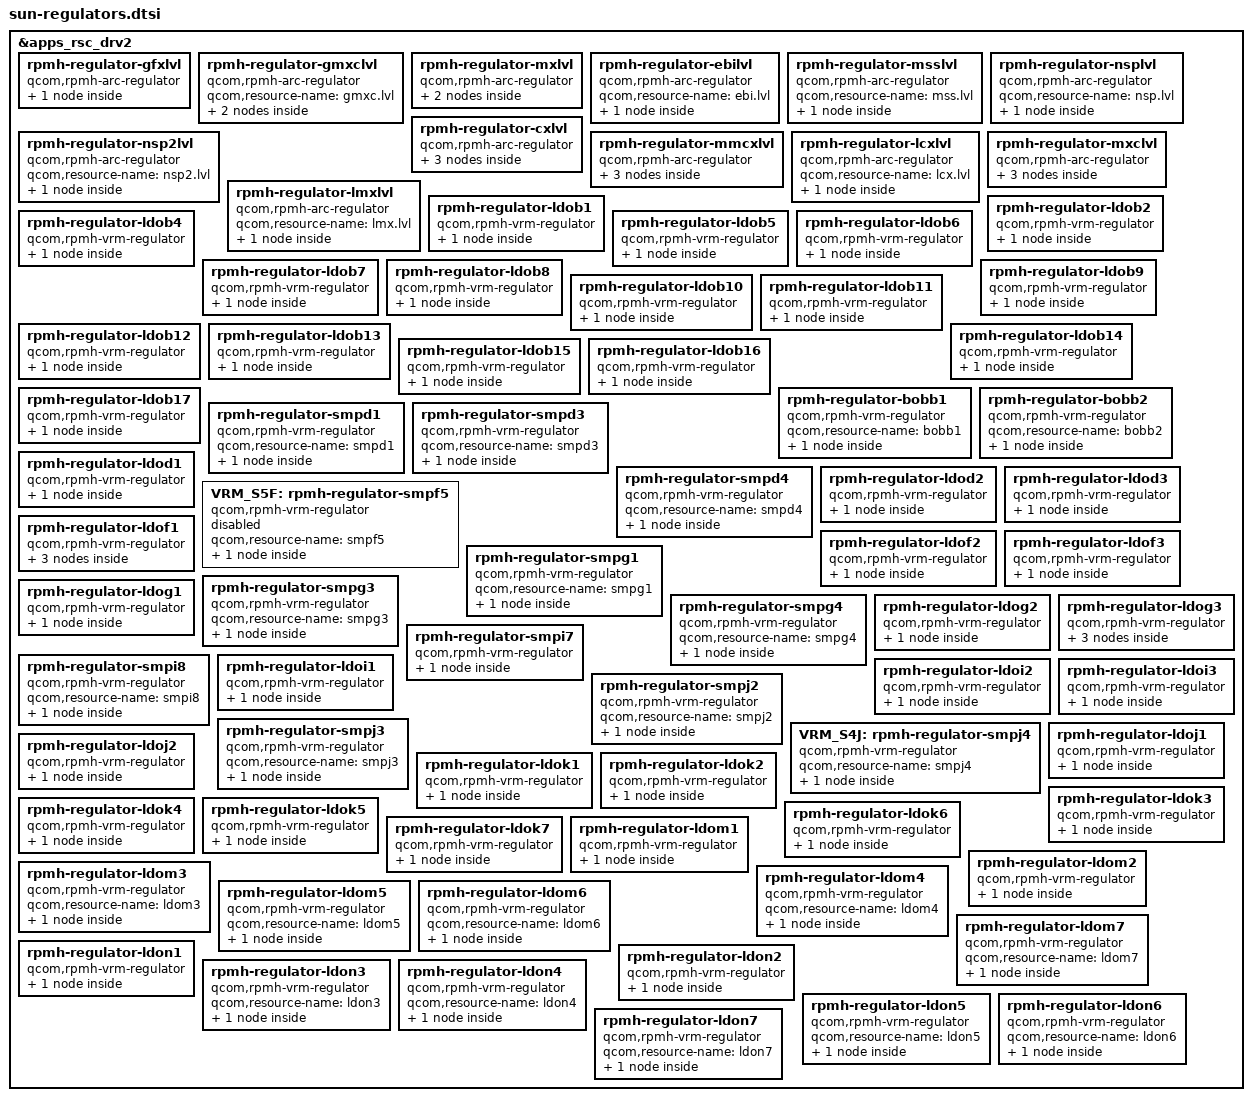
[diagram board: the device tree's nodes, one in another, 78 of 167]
// SPDX-License-Identifier: BSD-3-Clause
/*
 * Copyright (c) 2023-2024 Qualcomm Innovation Center, Inc. All rights reserved.
 */

#include <dt-bindings/regulator/qcom,rpmh-regulator-levels.h>

&apps_rsc_drv2 {
	rpmh-regulator-gfxlvl {
		compatible = "qcom,rpmh-arc-regulator";
		qcom,resource-name = "gfx.lvl";
		proxy-supply = <&VDD_GFX_LEVEL>;

		VDD_GFX_LEVEL: S5D_LEVEL:
		pm_v8d_s5_level: regulator-pm-v8d-s5-level {
			regulator-name = "pm_v8d_s5_level";
			qcom,set = <RPMH_REGULATOR_SET_ALL>;
			regulator-min-microvolt =
				<RPMH_REGULATOR_LEVEL_RETENTION>;
			regulator-max-microvolt =
				<RPMH_REGULATOR_LEVEL_MAX>;
			qcom,init-voltage-level =
				<RPMH_REGULATOR_LEVEL_RETENTION>;
			qcom,proxy-consumer-enable;
			qcom,proxy-consumer-voltage =
				<RPMH_REGULATOR_LEVEL_LOW_SVS
				 RPMH_REGULATOR_LEVEL_MAX>;
		};
	};

	rpmh-regulator-gmxclvl {
		compatible = "qcom,rpmh-arc-regulator";
		qcom,resource-name = "gmxc.lvl";

		VDD_GFX_MXC_LEVEL: S2D_LEVEL:
		pm_v8d_s2_level: regulator-pm-v8d-s2-level {
			regulator-name = "pm_v8d_s2_level";
			qcom,set = <RPMH_REGULATOR_SET_ALL>;
			regulator-min-microvolt =
				<RPMH_REGULATOR_LEVEL_RETENTION>;
			regulator-max-microvolt =
				<RPMH_REGULATOR_LEVEL_MAX>;
			qcom,init-voltage-level =
				<RPMH_REGULATOR_LEVEL_RETENTION>;
		};

		VDD_GFX_MXC_GFX_VOTER_LEVEL: VDD_GFX_GFX_MXC_VOTER_LEVEL:
		regulator-pm-v8d-s2-gfx-voter-level {
			regulator-name = "pm_v8d_s2_gfx_voter_level";
			pm_v8d_s2_gfx_voter_level-parent-supply =
				<&VDD_GFX_LEVEL>;
			qcom,set = <RPMH_REGULATOR_SET_ALL>;
			regulator-min-microvolt =
				<RPMH_REGULATOR_LEVEL_MIN_SVS>;
			regulator-max-microvolt =
				<RPMH_REGULATOR_LEVEL_MAX>;
			qcom,init-voltage-level =
				<RPMH_REGULATOR_LEVEL_MIN_SVS>;
		};
	};

	rpmh-regulator-mxlvl {
		compatible = "qcom,rpmh-arc-regulator";
		qcom,resource-name = "mx.lvl";
		proxy-supply = <&VDD_MXA_LEVEL>;

		VDD_MXA_LEVEL: VDD_MX_LEVEL: S6F_LEVEL:
		pm_v6f_s6_level: S8F_LEVEL: pm_v8f_s8_level:
		regulator-vdd-mxa-level {
			regulator-name = "pm_v6f_s6_level";
			qcom,set = <RPMH_REGULATOR_SET_ALL>;
			regulator-min-microvolt =
				<RPMH_REGULATOR_LEVEL_RETENTION>;
			regulator-max-microvolt =
				<RPMH_REGULATOR_LEVEL_MAX>;
			qcom,init-voltage-level =
				<RPMH_REGULATOR_LEVEL_TURBO>;
			qcom,proxy-consumer-enable;
			qcom,proxy-consumer-voltage =
				<RPMH_REGULATOR_LEVEL_TURBO
				 RPMH_REGULATOR_LEVEL_MAX>;
		};

		VDD_MXA_LEVEL_AO: VDD_MX_LEVEL_AO: S6F_LEVEL_AO:
		pm_v6f_s6_level_ao: S8F_LEVEL_AO: pm_v8f_s8_level_ao:
		regulator-vdd-mxa-level-ao {
			regulator-name = "pm_v6f_s6_level_ao";
			qcom,set = <RPMH_REGULATOR_SET_ACTIVE>;
			regulator-min-microvolt =
				<RPMH_REGULATOR_LEVEL_RETENTION>;
			regulator-max-microvolt =
				<RPMH_REGULATOR_LEVEL_MAX>;
			qcom,init-voltage-level =
				<RPMH_REGULATOR_LEVEL_RETENTION>;
		};
	};

	rpmh-regulator-ebilvl {
		compatible = "qcom,rpmh-arc-regulator";
		qcom,resource-name = "ebi.lvl";

		VDD_EBI_LEVEL: S2G_LEVEL:
		pm_v8g_s2_level: regulator-pm-v8g-s2-level {
			regulator-name = "pm_v8g_s2_level";
			qcom,set = <RPMH_REGULATOR_SET_ALL>;
			regulator-min-microvolt =
				<RPMH_REGULATOR_LEVEL_RETENTION>;
			regulator-max-microvolt =
				<RPMH_REGULATOR_LEVEL_MAX>;
			qcom,init-voltage-level =
				<RPMH_REGULATOR_LEVEL_RETENTION>;
		};
	};

	rpmh-regulator-msslvl {
		compatible = "qcom,rpmh-arc-regulator";
		qcom,resource-name = "mss.lvl";

		VDD_MODEM_LEVEL: S5G_LEVEL:
		pm_v8g_s5_level: regulator-pm-v8g-s5-level {
			regulator-name = "pm_v8g_s5_level";
			qcom,set = <RPMH_REGULATOR_SET_ALL>;
			regulator-min-microvolt =
				<RPMH_REGULATOR_LEVEL_RETENTION>;
			regulator-max-microvolt =
				<RPMH_REGULATOR_LEVEL_MAX>;
			qcom,init-voltage-level =
				<RPMH_REGULATOR_LEVEL_RETENTION>;
		};
	};

	rpmh-regulator-nsplvl {
		compatible = "qcom,rpmh-arc-regulator";
		qcom,resource-name = "nsp.lvl";

		VDD_NSP1_LEVEL: S7G_LEVEL:
		pm_v8g_s7_level: regulator-pm-v8g-s7-level {
			regulator-name = "pm_v8g_s7_level";
			qcom,set = <RPMH_REGULATOR_SET_ALL>;
			regulator-min-microvolt =
				<RPMH_REGULATOR_LEVEL_RETENTION>;
			regulator-max-microvolt =
				<RPMH_REGULATOR_LEVEL_MAX>;
			qcom,init-voltage-level =
				<RPMH_REGULATOR_LEVEL_RETENTION>;
		};
	};

	rpmh-regulator-nsp2lvl {
		compatible = "qcom,rpmh-arc-regulator";
		qcom,resource-name = "nsp2.lvl";

		VDD_NSP2_LEVEL: S1I_LEVEL:
		pm_v8i_s1_level: regulator-pm-v8i-s1-level {
			regulator-name = "pm_v8i_s1_level";
			qcom,set = <RPMH_REGULATOR_SET_ALL>;
			regulator-min-microvolt =
				<RPMH_REGULATOR_LEVEL_RETENTION>;
			regulator-max-microvolt =
				<RPMH_REGULATOR_LEVEL_MAX>;
			qcom,init-voltage-level =
				<RPMH_REGULATOR_LEVEL_RETENTION>;
		};
	};

	rpmh-regulator-cxlvl {
		compatible = "qcom,rpmh-arc-regulator";
		qcom,resource-name = "cx.lvl";
		proxy-supply = <&VDD_CX_LEVEL>;

		VDD_CX_LEVEL: S1J_LEVEL:
		pm_v6j_s1_level: regulator-pm-v6j-s1-level {
			regulator-name = "pm_v6j_s1_level";
			qcom,set = <RPMH_REGULATOR_SET_ALL>;
			regulator-min-microvolt =
				<RPMH_REGULATOR_LEVEL_RETENTION>;
			regulator-max-microvolt =
				<RPMH_REGULATOR_LEVEL_MAX>;
			qcom,init-voltage-level =
				<RPMH_REGULATOR_LEVEL_TURBO>;
			qcom,proxy-consumer-enable;
			qcom,proxy-consumer-voltage =
				<RPMH_REGULATOR_LEVEL_TURBO
				 RPMH_REGULATOR_LEVEL_MAX>;
		};

		VDD_CX_LEVEL_AO: S1J_LEVEL_AO:
		pm_v6j_s1_level_ao: regulator-pm-v6j-s1-level-ao {
			regulator-name = "pm_v6j_s1_level_ao";
			qcom,set = <RPMH_REGULATOR_SET_ACTIVE>;
			regulator-min-microvolt =
				<RPMH_REGULATOR_LEVEL_RETENTION>;
			regulator-max-microvolt =
				<RPMH_REGULATOR_LEVEL_MAX>;
			qcom,init-voltage-level =
				<RPMH_REGULATOR_LEVEL_RETENTION>;
		};

		VDD_CX_MMCX_SUPPLY_LEVEL: regulator-pm-v6j-s1-mmcx-sup-level {
			regulator-name = "pm_v6j_s1_mmcx_sup_level";
			qcom,set = <RPMH_REGULATOR_SET_ALL>;
			regulator-min-microvolt =
				<RPMH_REGULATOR_LEVEL_MIN_SVS>;
			regulator-max-microvolt =
				<RPMH_REGULATOR_LEVEL_MAX>;
			qcom,init-voltage-level =
				<RPMH_REGULATOR_LEVEL_MIN_SVS>;
		};
	};

	rpmh-regulator-mmcxlvl {
		compatible = "qcom,rpmh-arc-regulator";
		qcom,resource-name = "mmcx.lvl";
		proxy-supply = <&VDD_MMCX_LEVEL>;

		VDD_MMCX_LEVEL: VDD_MM_LEVEL: S3I_LEVEL:
		pm_v8i_s3_level: regulator-pm-v8i-s3-level {
			regulator-name = "pm_v8i_s3_level";
			qcom,set = <RPMH_REGULATOR_SET_ALL>;
			pm_v8i_s3_level-parent-supply =
				<&VDD_CX_MMCX_SUPPLY_LEVEL>;
			regulator-min-microvolt =
				<RPMH_REGULATOR_LEVEL_LOW_SVS_D1>;
			regulator-max-microvolt =
				<RPMH_REGULATOR_LEVEL_MAX>;
			qcom,init-voltage-level =
				<RPMH_REGULATOR_LEVEL_TURBO>;
			qcom,proxy-consumer-enable;
			qcom,proxy-consumer-voltage =
				<RPMH_REGULATOR_LEVEL_TURBO
				 RPMH_REGULATOR_LEVEL_MAX>;
		};

		VDD_MMCX_LEVEL_AO: VDD_MM_LEVEL_AO: S3I_LEVEL_AO:
		pm_v8i_s3_level_ao: regulator-pm-v8i-s3-level-ao {
			regulator-name = "pm_v8i_s3_level_ao";
			qcom,set = <RPMH_REGULATOR_SET_ACTIVE>;
			regulator-min-microvolt =
				<RPMH_REGULATOR_LEVEL_LOW_SVS_D1>;
			regulator-max-microvolt =
				<RPMH_REGULATOR_LEVEL_MAX>;
			qcom,init-voltage-level =
				<RPMH_REGULATOR_LEVEL_LOW_SVS_D1>;
		};

		regulator-pm-v8i-s3-level-so {
			regulator-name = "pm_v8i_s3_level_so";
			qcom,set = <RPMH_REGULATOR_SET_SLEEP>;
			regulator-min-microvolt =
				<RPMH_REGULATOR_LEVEL_LOW_SVS_D1>;
			regulator-max-microvolt =
				<RPMH_REGULATOR_LEVEL_MAX>;
			qcom,init-voltage-level =
				<RPMH_REGULATOR_LEVEL_LOW_SVS_D1>;
		};
	};

	rpmh-regulator-lcxlvl {
		compatible = "qcom,rpmh-arc-regulator";
		qcom,resource-name = "lcx.lvl";

		VDD_LPI_CX_LEVEL: S5I_LEVEL:
		pm_v8i_s5_level: regulator-pm-v8i-s5-level {
			regulator-name = "pm_v8i_s5_level";
			qcom,set = <RPMH_REGULATOR_SET_ALL>;
			regulator-min-microvolt =
				<RPMH_REGULATOR_LEVEL_RETENTION>;
			regulator-max-microvolt =
				<RPMH_REGULATOR_LEVEL_MAX>;
			qcom,init-voltage-level =
				<RPMH_REGULATOR_LEVEL_RETENTION>;
		};
	};

	rpmh-regulator-mxclvl {
		compatible = "qcom,rpmh-arc-regulator";
		qcom,resource-name = "mxc.lvl";
		proxy-supply = <&VDD_MXC_LEVEL>;

		VDD_MXC_LEVEL: S6I_LEVEL:
		pm_v8i_s6_level: regulator-pm-v8i-s6-level {
			regulator-name = "pm_v8i_s6_level";
			qcom,set = <RPMH_REGULATOR_SET_ALL>;
			regulator-min-microvolt =
				<RPMH_REGULATOR_LEVEL_RETENTION>;
			regulator-max-microvolt =
				<RPMH_REGULATOR_LEVEL_MAX>;
			qcom,init-voltage-level =
				<RPMH_REGULATOR_LEVEL_TURBO>;
			qcom,proxy-consumer-enable;
			qcom,proxy-consumer-voltage =
				<RPMH_REGULATOR_LEVEL_TURBO
				 RPMH_REGULATOR_LEVEL_MAX>;
		};

		VDD_MXC_LEVEL_AO: S6I_LEVEL_AO:
		pm_v8i_s6_level_ao: regulator-pm-v8i-s6-level-ao {
			regulator-name = "pm_v8i_s6_level_ao";
			qcom,set = <RPMH_REGULATOR_SET_ACTIVE>;
			regulator-min-microvolt =
				<RPMH_REGULATOR_LEVEL_RETENTION>;
			regulator-max-microvolt =
				<RPMH_REGULATOR_LEVEL_MAX>;
			qcom,init-voltage-level =
				<RPMH_REGULATOR_LEVEL_RETENTION>;
		};

		VDD_MXC_MMCX_VOTER_LEVEL: VDD_MXC_MM_VOTER_LEVEL:
		VDD_MM_MXC_VOTER_LEVEL: regulator-pm-v8i-s6-mmcx-voter-level {
			regulator-name = "pm_v8i_s6_mmcx_voter_level";
			pm_v8i_s6_mmcx_voter_level-parent-supply =
				<&VDD_MMCX_LEVEL>;
			qcom,set = <RPMH_REGULATOR_SET_ALL>;
			regulator-min-microvolt =
				<RPMH_REGULATOR_LEVEL_MIN_SVS>;
			regulator-max-microvolt =
				<RPMH_REGULATOR_LEVEL_MAX>;
			qcom,init-voltage-level =
				<RPMH_REGULATOR_LEVEL_MIN_SVS>;
		};
	};

	rpmh-regulator-lmxlvl {
		compatible = "qcom,rpmh-arc-regulator";
		qcom,resource-name = "lmx.lvl";

		VDD_LPI_MX_LEVEL: L3J_LEVEL:
		pm_v6j_l3_level: regulator-pm-v6j-l3-level {
			regulator-name = "pm_v6j_l3_level";
			qcom,set = <RPMH_REGULATOR_SET_ALL>;
			regulator-min-microvolt =
				<RPMH_REGULATOR_LEVEL_RETENTION>;
			regulator-max-microvolt =
				<RPMH_REGULATOR_LEVEL_MAX>;
			qcom,init-voltage-level =
				<RPMH_REGULATOR_LEVEL_RETENTION>;
		};
	};

	rpmh-regulator-ldob1 {
		compatible = "qcom,rpmh-vrm-regulator";
		qcom,resource-name = "ldob1";
		qcom,regulator-type = "pmic5-ldo";
		qcom,supported-modes =
			<RPMH_REGULATOR_MODE_LPM
			 RPMH_REGULATOR_MODE_HPM>;
		qcom,mode-threshold-currents = <0 30000>;

		L1B: pm_humu_l1: regulator-pm-humu-l1 {
			regulator-name = "pm_humu_l1";
			qcom,set = <RPMH_REGULATOR_SET_ALL>;
			regulator-min-microvolt = <1800000>;
			regulator-max-microvolt = <1800000>;
			qcom,init-voltage = <1800000>;
			qcom,init-mode = <RPMH_REGULATOR_MODE_HPM>;
		};
	};

	rpmh-regulator-ldob2 {
		compatible = "qcom,rpmh-vrm-regulator";
		qcom,resource-name = "ldob2";
		qcom,regulator-type = "pmic5-ldo";
		qcom,supported-modes =
			<RPMH_REGULATOR_MODE_LPM
			 RPMH_REGULATOR_MODE_HPM>;
		qcom,mode-threshold-currents = <0 10000>;

		L2B: pm_humu_l2: regulator-pm-humu-l2 {
			regulator-name = "pm_humu_l2";
			qcom,set = <RPMH_REGULATOR_SET_ALL>;
			regulator-min-microvolt = <3008000>;
			regulator-max-microvolt = <3048000>;
			qcom,init-voltage = <3008000>;
			qcom,init-mode = <RPMH_REGULATOR_MODE_HPM>;
		};
	};

	rpmh-regulator-ldob4 {
		compatible = "qcom,rpmh-vrm-regulator";
		qcom,resource-name = "ldob4";
		qcom,regulator-type = "pmic5-ldo";
		qcom,supported-modes =
			<RPMH_REGULATOR_MODE_LPM
			 RPMH_REGULATOR_MODE_HPM>;
		qcom,mode-threshold-currents = <0 30000>;

		L4B: pm_humu_l4: regulator-pm-humu-l4 {
			regulator-name = "pm_humu_l4";
			qcom,set = <RPMH_REGULATOR_SET_ALL>;
			regulator-min-microvolt = <1800000>;
			regulator-max-microvolt = <1800000>;
			qcom,init-voltage = <1800000>;
			qcom,init-mode = <RPMH_REGULATOR_MODE_HPM>;
		};
	};

	rpmh-regulator-ldob5 {
		compatible = "qcom,rpmh-vrm-regulator";
		qcom,resource-name = "ldob5";
		qcom,regulator-type = "pmic5-ldo";
		qcom,supported-modes =
			<RPMH_REGULATOR_MODE_LPM
			 RPMH_REGULATOR_MODE_HPM>;
		qcom,mode-threshold-currents = <0 10000>;

		L5B: pm_humu_l5: regulator-pm-humu-l5 {
			regulator-name = "pm_humu_l5";
			qcom,set = <RPMH_REGULATOR_SET_ALL>;
			regulator-min-microvolt = <3100000>;
			regulator-max-microvolt = <3148000>;
			qcom,init-voltage = <3104000>;
			qcom,init-mode = <RPMH_REGULATOR_MODE_HPM>;
		};
	};

	rpmh-regulator-ldob6 {
		compatible = "qcom,rpmh-vrm-regulator";
		qcom,resource-name = "ldob6";
		qcom,regulator-type = "pmic5-ldo";
		qcom,supported-modes =
			<RPMH_REGULATOR_MODE_LPM
			 RPMH_REGULATOR_MODE_HPM>;
		qcom,mode-threshold-currents = <0 10000>;

		L6B: pm_humu_l6: regulator-pm-humu-l6 {
			regulator-name = "pm_humu_l6";
			qcom,set = <RPMH_REGULATOR_SET_ALL>;
			regulator-min-microvolt = <1800000>;
			regulator-max-microvolt = <3008000>;
			qcom,init-voltage = <1800000>;
			qcom,init-mode = <RPMH_REGULATOR_MODE_HPM>;
		};
	};

	rpmh-regulator-ldob7 {
		compatible = "qcom,rpmh-vrm-regulator";
		qcom,resource-name = "ldob7";
		qcom,regulator-type = "pmic5-ldo";
		qcom,supported-modes =
			<RPMH_REGULATOR_MODE_LPM
			 RPMH_REGULATOR_MODE_HPM>;
		qcom,mode-threshold-currents = <0 10000>;

		L7B: pm_humu_l7: regulator-pm-humu-l7 {
			regulator-name = "pm_humu_l7";
			qcom,set = <RPMH_REGULATOR_SET_ALL>;
			regulator-min-microvolt = <1800000>;
			regulator-max-microvolt = <3008000>;
			qcom,init-voltage = <1800000>;
			qcom,init-mode = <RPMH_REGULATOR_MODE_HPM>;
		};
	};

	rpmh-regulator-ldob8 {
		compatible = "qcom,rpmh-vrm-regulator";
		qcom,resource-name = "ldob8";
		qcom,regulator-type = "pmic5-ldo";
		qcom,supported-modes =
			<RPMH_REGULATOR_MODE_LPM
			 RPMH_REGULATOR_MODE_HPM>;
		qcom,mode-threshold-currents = <0 10000>;

		L8B: pm_humu_l8: regulator-pm-humu-l8 {
			regulator-name = "pm_humu_l8";
			qcom,set = <RPMH_REGULATOR_SET_ALL>;
			regulator-min-microvolt = <1800000>;
			regulator-max-microvolt = <3008000>;
			qcom,init-voltage = <1800000>;
			qcom,init-mode = <RPMH_REGULATOR_MODE_HPM>;
		};
	};

	rpmh-regulator-ldob9 {
		compatible = "qcom,rpmh-vrm-regulator";
		qcom,resource-name = "ldob9";
		qcom,regulator-type = "pmic5-ldo";
		qcom,supported-modes =
			<RPMH_REGULATOR_MODE_LPM
			 RPMH_REGULATOR_MODE_HPM>;
		qcom,mode-threshold-currents = <0 10000>;

		L9B: pm_humu_l9: regulator-pm-humu-l9 {
			regulator-name = "pm_humu_l9";
			qcom,set = <RPMH_REGULATOR_SET_ALL>;
			regulator-min-microvolt = <2960000>;
			regulator-max-microvolt = <3008000>;
			qcom,init-voltage = <2960000>;
			qcom,init-mode = <RPMH_REGULATOR_MODE_HPM>;
		};
	};

	rpmh-regulator-ldob10 {
		compatible = "qcom,rpmh-vrm-regulator";
		qcom,resource-name = "ldob10";
		qcom,regulator-type = "pmic5-ldo";
		qcom,supported-modes =
			<RPMH_REGULATOR_MODE_LPM
			 RPMH_REGULATOR_MODE_HPM>;
		qcom,mode-threshold-currents = <0 30000>;

		L10B: pm_humu_l10: regulator-pm-humu-l10 {
			regulator-name = "pm_humu_l10";
			qcom,set = <RPMH_REGULATOR_SET_ALL>;
			regulator-min-microvolt = <1800000>;
			regulator-max-microvolt = <1800000>;
			qcom,init-voltage = <1800000>;
			qcom,init-mode = <RPMH_REGULATOR_MODE_HPM>;
		};
	};

	rpmh-regulator-ldob11 {
		compatible = "qcom,rpmh-vrm-regulator";
		qcom,resource-name = "ldob11";
		qcom,regulator-type = "pmic5-ldo";
		qcom,supported-modes =
			<RPMH_REGULATOR_MODE_LPM
			 RPMH_REGULATOR_MODE_HPM>;
		qcom,mode-threshold-currents = <0 30000>;
		proxy-supply = <&L11B>;

		L11B: pm_humu_l11: regulator-pm-humu-l11 {
			regulator-name = "pm_humu_l11";
			qcom,set = <RPMH_REGULATOR_SET_ALL>;
			regulator-min-microvolt = <1064000>;
			regulator-max-microvolt = <1292000>;
			qcom,init-voltage = <1064000>;
			qcom,init-mode = <RPMH_REGULATOR_MODE_HPM>;
			qcom,proxy-consumer-enable;
		};
	};

	rpmh-regulator-ldob12 {
		compatible = "qcom,rpmh-vrm-regulator";
		qcom,resource-name = "ldob12";
		qcom,regulator-type = "pmic5-ldo";
		qcom,supported-modes =
			<RPMH_REGULATOR_MODE_LPM
			 RPMH_REGULATOR_MODE_HPM>;
		qcom,mode-threshold-currents = <0 30000>;
		proxy-supply = <&L12B>;

		L12B: pm_humu_l12: regulator-pm-humu-l12 {
			regulator-name = "pm_humu_l12";
			qcom,set = <RPMH_REGULATOR_SET_ALL>;
			regulator-min-microvolt = <1200000>;
			regulator-max-microvolt = <1800000>;
			qcom,init-voltage = <1800000>;
			qcom,init-mode = <RPMH_REGULATOR_MODE_HPM>;
			qcom,proxy-consumer-enable;
		};
	};

	rpmh-regulator-ldob13 {
		compatible = "qcom,rpmh-vrm-regulator";
		qcom,resource-name = "ldob13";
		qcom,regulator-type = "pmic5-ldo";
		qcom,supported-modes =
			<RPMH_REGULATOR_MODE_LPM
			 RPMH_REGULATOR_MODE_HPM>;
		qcom,mode-threshold-currents = <0 10000>;
		proxy-supply = <&L13B>;

		L13B: pm_humu_l13: regulator-pm-humu-l13 {
			regulator-name = "pm_humu_l13";
			qcom,set = <RPMH_REGULATOR_SET_ALL>;
			regulator-min-microvolt = <3000000>;
			regulator-max-microvolt = <3000000>;
			qcom,init-voltage = <3000000>;
			qcom,init-mode = <RPMH_REGULATOR_MODE_HPM>;
			qcom,proxy-consumer-enable;
		};
	};

	rpmh-regulator-ldob14 {
		compatible = "qcom,rpmh-vrm-regulator";
		qcom,resource-name = "ldob14";
		qcom,regulator-type = "pmic5-ldo";
		qcom,supported-modes =
			<RPMH_REGULATOR_MODE_LPM
			 RPMH_REGULATOR_MODE_HPM>;
		qcom,mode-threshold-currents = <0 10000>;

		L14B: pm_humu_l14: regulator-pm-humu-l14 {
			regulator-name = "pm_humu_l14";
			qcom,set = <RPMH_REGULATOR_SET_ALL>;
			regulator-min-microvolt = <3200000>;
			regulator-max-microvolt = <3200000>;
			qcom,init-voltage = <3200000>;
			qcom,init-mode = <RPMH_REGULATOR_MODE_HPM>;
		};
	};

	rpmh-regulator-ldob15 {
		compatible = "qcom,rpmh-vrm-regulator";
		qcom,resource-name = "ldob15";
		qcom,regulator-type = "pmic5-ldo";
		qcom,supported-modes =
			<RPMH_REGULATOR_MODE_LPM
			 RPMH_REGULATOR_MODE_HPM>;
		qcom,mode-threshold-currents = <0 30000>;

		L15B: pm_humu_l15: regulator-pm-humu-l15 {
			regulator-name = "pm_humu_l15";
			qcom,set = <RPMH_REGULATOR_SET_ALL>;
			regulator-min-microvolt = <1800000>;
			regulator-max-microvolt = <1800000>;
			qcom,init-voltage = <1800000>;
			qcom,init-mode = <RPMH_REGULATOR_MODE_HPM>;
		};
	};

	rpmh-regulator-ldob16 {
		compatible = "qcom,rpmh-vrm-regulator";
		qcom,resource-name = "ldob16";
		qcom,regulator-type = "pmic5-ldo";
		qcom,supported-modes =
			<RPMH_REGULATOR_MODE_LPM
			 RPMH_REGULATOR_MODE_HPM>;
		qcom,mode-threshold-currents = <0 10000>;

		L16B: pm_humu_l16: regulator-pm-humu-l16 {
			regulator-name = "pm_humu_l16";
			qcom,set = <RPMH_REGULATOR_SET_ALL>;
			regulator-min-microvolt = <2800000>;
			regulator-max-microvolt = <2800000>;
			qcom,init-voltage = <2800000>;
			qcom,init-mode = <RPMH_REGULATOR_MODE_HPM>;
		};
	};

	rpmh-regulator-ldob17 {
		compatible = "qcom,rpmh-vrm-regulator";
		qcom,resource-name = "ldob17";
		qcom,regulator-type = "pmic5-ldo";
		qcom,supported-modes =
			<RPMH_REGULATOR_MODE_LPM
			 RPMH_REGULATOR_MODE_HPM>;
		qcom,mode-threshold-currents = <0 10000>;

		L17B: pm_humu_l17: regulator-pm-humu-l17 {
			regulator-name = "pm_humu_l17";
			qcom,set = <RPMH_REGULATOR_SET_ALL>;
			regulator-min-microvolt = <2504000>;
			regulator-max-microvolt = <2504000>;
			qcom,init-voltage = <2504000>;
			qcom,init-mode = <RPMH_REGULATOR_MODE_HPM>;
		};
	};

	rpmh-regulator-bobb1 {
		compatible = "qcom,rpmh-vrm-regulator";
		qcom,resource-name = "bobb1";

		BOB1: pm_humu_bob1: regulator-pm-humu-bob1 {
			regulator-name = "pm_humu_bob1";
			qcom,set = <RPMH_REGULATOR_SET_ALL>;
			regulator-min-microvolt = <3008000>;
			regulator-max-microvolt = <4000000>;
			qcom,init-voltage = <3296000>;
		};
	};

	rpmh-regulator-bobb2 {
		compatible = "qcom,rpmh-vrm-regulator";
		qcom,resource-name = "bobb2";

		BOB2: pm_humu_bob2: regulator-pm-humu-bob2 {
			regulator-name = "pm_humu_bob2";
			qcom,set = <RPMH_REGULATOR_SET_ALL>;
			regulator-min-microvolt = <2704000>;
			regulator-max-microvolt = <3008000>;
			qcom,init-voltage = <2720000>;
		};
	};

	rpmh-regulator-smpd1 {
		compatible = "qcom,rpmh-vrm-regulator";
		qcom,resource-name = "smpd1";

		S1D: pm_v8d_s1: regulator-pm-v8d-s1 {
			regulator-name = "pm_v8d_s1";
			qcom,set = <RPMH_REGULATOR_SET_ALL>;
			regulator-min-microvolt = <880000>;
			regulator-max-microvolt = <1100000>;
			qcom,init-voltage = <976000>;
		};
	};

	rpmh-regulator-smpd3 {
		compatible = "qcom,rpmh-vrm-regulator";
		qcom,resource-name = "smpd3";

		S3D: pm_v8d_s3: regulator-pm-v8d-s3 {
			regulator-name = "pm_v8d_s3";
			qcom,set = <RPMH_REGULATOR_SET_ALL>;
			regulator-min-microvolt = <1200000>;
			regulator-max-microvolt = <1300000>;
			qcom,init-voltage = <1224000>;
		};
	};

	rpmh-regulator-smpd4 {
		compatible = "qcom,rpmh-vrm-regulator";
		qcom,resource-name = "smpd4";

		S4D: pm_v8d_s4: regulator-pm-v8d-s4 {
			regulator-name = "pm_v8d_s4";
			qcom,set = <RPMH_REGULATOR_SET_ALL>;
			regulator-min-microvolt = <500000>;
			regulator-max-microvolt = <1036000>;
			qcom,init-voltage = <852000>;
		};
	};

	rpmh-regulator-ldod1 {
		compatible = "qcom,rpmh-vrm-regulator";
		qcom,resource-name = "ldod1";
		qcom,regulator-type = "pmic5-ldo";
		qcom,supported-modes =
			<RPMH_REGULATOR_MODE_LPM
			 RPMH_REGULATOR_MODE_HPM>;
		qcom,mode-threshold-currents = <0 30000>;

		L1D: pm_v8d_l1: regulator-pm-v8d-l1 {
			regulator-name = "pm_v8d_l1";
			qcom,set = <RPMH_REGULATOR_SET_ALL>;
			regulator-min-microvolt = <1200000>;
			regulator-max-microvolt = <1200000>;
			qcom,init-voltage = <1200000>;
			qcom,init-mode = <RPMH_REGULATOR_MODE_HPM>;
		};
	};

	rpmh-regulator-ldod2 {
		compatible = "qcom,rpmh-vrm-regulator";
		qcom,resource-name = "ldod2";
		qcom,regulator-type = "pmic5-ldo";
		qcom,supported-modes =
			<RPMH_REGULATOR_MODE_LPM
			 RPMH_REGULATOR_MODE_HPM>;
		qcom,mode-threshold-currents = <0 30000>;

		L2D: pm_v8d_l2: regulator-pm-v8d-l2 {
			regulator-name = "pm_v8d_l2";
			qcom,set = <RPMH_REGULATOR_SET_ALL>;
			regulator-min-microvolt = <880000>;
			regulator-max-microvolt = <912000>;
			qcom,init-voltage = <880000>;
			qcom,init-mode = <RPMH_REGULATOR_MODE_HPM>;
		};
	};

	rpmh-regulator-ldod3 {
		compatible = "qcom,rpmh-vrm-regulator";
		qcom,resource-name = "ldod3";
		qcom,regulator-type = "pmic5-ldo";
		qcom,supported-modes =
			<RPMH_REGULATOR_MODE_LPM
			 RPMH_REGULATOR_MODE_HPM>;
		qcom,mode-threshold-currents = <0 30000>;

		L3D: pm_v8d_l3: regulator-pm-v8d-l3 {
			regulator-name = "pm_v8d_l3";
			qcom,set = <RPMH_REGULATOR_SET_ALL>;
			regulator-min-microvolt = <880000>;
			regulator-max-microvolt = <920000>;
			qcom,init-voltage = <880000>;
			qcom,init-mode = <RPMH_REGULATOR_MODE_HPM>;
		};
	};

	VRM_S5F: rpmh-regulator-smpf5 {
		compatible = "qcom,rpmh-vrm-regulator";
		qcom,resource-name = "smpf5";
		status = "disabled";

		S5F: pm_v8f_s5: regulator-pm-v8f-s5 {
			regulator-name = "pm_v8f_s5";
			qcom,set = <RPMH_REGULATOR_SET_ALL>;
			regulator-min-microvolt = <500000>;
			regulator-max-microvolt = <1000000>;
			qcom,init-voltage = <852000>;
			status = "disabled";
		};
	};

	rpmh-regulator-ldof1 {
		compatible = "qcom,rpmh-vrm-regulator";
		qcom,resource-name = "ldof1";
		qcom,regulator-type = "pmic5-ldo";
		qcom,supported-modes =
			<RPMH_REGULATOR_MODE_LPM
			 RPMH_REGULATOR_MODE_HPM>;
		qcom,mode-threshold-currents = <0 30000>;
		qcom,send-defaults;

		L1F: pm_v6f_l1: pm_v8f_l1: regulator-pm-vxf-l1 {
			regulator-name = "pm_v6f_l1";
			qcom,set = <RPMH_REGULATOR_SET_ALL>;
			regulator-min-microvolt = <880000>;
			regulator-max-microvolt = <920000>;
			qcom,init-voltage = <880000>;
			qcom,init-mode = <RPMH_REGULATOR_MODE_HPM>;
		};

		L1F_AO: pm_v6f_l1_ao: pm_v8f_l1_ao: regulator-pm-vxf-l1-ao {
			regulator-name = "pm_v6f_l1_ao";
			qcom,set = <RPMH_REGULATOR_SET_ACTIVE>;
			regulator-min-microvolt = <880000>;
			regulator-max-microvolt = <920000>;
			qcom,init-voltage = <880000>;
			qcom,init-mode = <RPMH_REGULATOR_MODE_HPM>;
			regulator-always-on;
		};

		L1F_SO: pm_v6f_l1_so: pm_v8f_l1_so: regulator-pm-vxf-l1-so {
			regulator-name = "pm_v6f_l1_so";
			qcom,set = <RPMH_REGULATOR_SET_SLEEP>;
			regulator-min-microvolt = <880000>;
			regulator-max-microvolt = <920000>;
			qcom,init-voltage = <880000>;
			qcom,init-mode = <RPMH_REGULATOR_MODE_LPM>;
			qcom,init-enable = <0>;
		};
	};

	rpmh-regulator-ldof2 {
		compatible = "qcom,rpmh-vrm-regulator";
		qcom,resource-name = "ldof2";
		qcom,regulator-type = "pmic5-ldo";
		qcom,supported-modes =
			<RPMH_REGULATOR_MODE_LPM
			 RPMH_REGULATOR_MODE_HPM>;
		qcom,mode-threshold-currents = <0 30000>;

		L2F: pm_v6f_l2: pm_v8f_l2: regulator-pm-vxf-l2 {
			regulator-name = "pm_v6f_l2";
			qcom,set = <RPMH_REGULATOR_SET_ALL>;
			regulator-min-microvolt = <1200000>;
			regulator-max-microvolt = <1200000>;
			qcom,init-voltage = <1200000>;
			qcom,init-mode = <RPMH_REGULATOR_MODE_LPM>;
			regulator-always-on;
		};
	};

	rpmh-regulator-ldof3 {
		compatible = "qcom,rpmh-vrm-regulator";
		qcom,resource-name = "ldof3";
		qcom,regulator-type = "pmic5-ldo";
		qcom,supported-modes =
			<RPMH_REGULATOR_MODE_LPM
			 RPMH_REGULATOR_MODE_HPM>;
		qcom,mode-threshold-currents = <0 30000>;

		L3F: pm_v6f_l3: pm_v8f_l3: regulator-pm-vxf-l3 {
			regulator-name = "pm_v6f_l3";
			qcom,set = <RPMH_REGULATOR_SET_ALL>;
			regulator-min-microvolt = <1800000>;
			regulator-max-microvolt = <1800000>;
			qcom,init-voltage = <1800000>;
			qcom,init-mode = <RPMH_REGULATOR_MODE_LPM>;
			regulator-always-on;
		};
	};

	rpmh-regulator-smpg1 {
		compatible = "qcom,rpmh-vrm-regulator";
		qcom,resource-name = "smpg1";

		S1G: pm_v8g_s1: regulator-pm-v8g-s1 {
			regulator-name = "pm_v8g_s1";
			qcom,set = <RPMH_REGULATOR_SET_ALL>;
			regulator-min-microvolt = <300000>;
			regulator-max-microvolt = <700000>;
			qcom,init-voltage = <500000>;
		};
	};

	rpmh-regulator-smpg3 {
		compatible = "qcom,rpmh-vrm-regulator";
		qcom,resource-name = "smpg3";

		S3G: pm_v8g_s3: regulator-pm-v8g-s3 {
			regulator-name = "pm_v8g_s3";
			qcom,set = <RPMH_REGULATOR_SET_ALL>;
			regulator-min-microvolt = <1856000>;
			regulator-max-microvolt = <2000000>;
			qcom,init-voltage = <1856000>;
		};
	};

	rpmh-regulator-smpg4 {
		compatible = "qcom,rpmh-vrm-regulator";
		qcom,resource-name = "smpg4";

		S4G: pm_v8g_s4: regulator-pm-v8g-s4 {
			regulator-name = "pm_v8g_s4";
			qcom,set = <RPMH_REGULATOR_SET_ALL>;
			regulator-min-microvolt = <300000>;
			regulator-max-microvolt = <900000>;
			qcom,init-voltage = <752000>;
		};
	};

	rpmh-regulator-ldog1 {
		compatible = "qcom,rpmh-vrm-regulator";
		qcom,resource-name = "ldog1";
		qcom,regulator-type = "pmic5-ldo";
		qcom,supported-modes =
			<RPMH_REGULATOR_MODE_LPM
			 RPMH_REGULATOR_MODE_HPM>;
		qcom,mode-threshold-currents = <0 30000>;

		L1G: pm_v8g_l1: regulator-pm-v8g-l1 {
			regulator-name = "pm_v8g_l1";
			qcom,set = <RPMH_REGULATOR_SET_ALL>;
			regulator-min-microvolt = <912000>;
			regulator-max-microvolt = <936000>;
			qcom,init-voltage = <912000>;
			qcom,init-mode = <RPMH_REGULATOR_MODE_HPM>;
		};
	};

	rpmh-regulator-ldog2 {
		compatible = "qcom,rpmh-vrm-regulator";
		qcom,resource-name = "ldog2";
		qcom,regulator-type = "pmic5-ldo";
		qcom,supported-modes =
			<RPMH_REGULATOR_MODE_LPM
			 RPMH_REGULATOR_MODE_HPM>;
		qcom,mode-threshold-currents = <0 30000>;

		L2G: pm_v8g_l2: regulator-pm-v8g-l2 {
			regulator-name = "pm_v8g_l2";
			qcom,set = <RPMH_REGULATOR_SET_ALL>;
			regulator-min-microvolt = <1200000>;
			regulator-max-microvolt = <1860000>;
			qcom,init-voltage = <1800000>;
			qcom,init-mode = <RPMH_REGULATOR_MODE_HPM>;
		};
	};

	rpmh-regulator-ldog3 {
		compatible = "qcom,rpmh-vrm-regulator";
		qcom,resource-name = "ldog3";
		qcom,regulator-type = "pmic5-ldo";
		qcom,supported-modes =
			<RPMH_REGULATOR_MODE_LPM
			 RPMH_REGULATOR_MODE_HPM>;
		qcom,mode-threshold-currents = <0 30000>;
		proxy-supply = <&L3G>;
		qcom,send-defaults;

		L3G: pm_v8g_l3: regulator-pm-v8g-l3 {
			regulator-name = "pm_v8g_l3";
			qcom,set = <RPMH_REGULATOR_SET_ALL>;
			regulator-min-microvolt = <1200000>;
			regulator-max-microvolt = <1256000>;
			qcom,init-voltage = <1200000>;
			qcom,init-mode = <RPMH_REGULATOR_MODE_HPM>;
			qcom,proxy-consumer-enable;
		};

		L3G_AO: pm_v8g_l3_ao: regulator-pm-v8g-l3-ao {
			regulator-name = "pm_v8g_l3_ao";
			qcom,set = <RPMH_REGULATOR_SET_ACTIVE>;
			regulator-min-microvolt = <1200000>;
			regulator-max-microvolt = <1256000>;
			qcom,init-voltage = <1200000>;
			qcom,init-mode = <RPMH_REGULATOR_MODE_HPM>;
			regulator-always-on;
		};

		regulator-pm-v8g-l3-so {
			regulator-name = "pm_v8g_l3_so";
			qcom,set = <RPMH_REGULATOR_SET_SLEEP>;
			regulator-min-microvolt = <1200000>;
			regulator-max-microvolt = <1256000>;
			qcom,init-voltage = <1200000>;
			qcom,init-mode = <RPMH_REGULATOR_MODE_LPM>;
			qcom,init-enable = <0>;
		};
	};

	rpmh-regulator-smpi7 {
		compatible = "qcom,rpmh-vrm-regulator";
		qcom,resource-name = "smpi7";
		qcom,regulator-type = "pmic5-ftsmps";
		qcom,supported-modes =
			<RPMH_REGULATOR_MODE_RET
			 RPMH_REGULATOR_MODE_HPM>;
		qcom,mode-threshold-currents = <0 200000>;

		S7I: pm_v8i_s7: regulator-pm-v8i-s7 {
			regulator-name = "pm_v8i_s7";
			qcom,set = <RPMH_REGULATOR_SET_ALL>;
			regulator-min-microvolt = <1224000>;
			regulator-max-microvolt = <1340000>;
			qcom,init-voltage = <1256000>;
			qcom,init-mode = <RPMH_REGULATOR_MODE_RET>;
		};
	};

	rpmh-regulator-smpi8 {
		compatible = "qcom,rpmh-vrm-regulator";
		qcom,resource-name = "smpi8";

		S8I: pm_v8i_s8: regulator-pm-v8i-s8 {
			regulator-name = "pm_v8i_s8";
			qcom,set = <RPMH_REGULATOR_SET_ALL>;
			regulator-min-microvolt = <900000>;
			regulator-max-microvolt = <972000>;
			qcom,init-voltage = <904000>;
		};
	};

	rpmh-regulator-ldoi1 {
		compatible = "qcom,rpmh-vrm-regulator";
		qcom,resource-name = "ldoi1";
		qcom,regulator-type = "pmic5-ldo";
		qcom,supported-modes =
			<RPMH_REGULATOR_MODE_LPM
			 RPMH_REGULATOR_MODE_HPM>;
		qcom,mode-threshold-currents = <0 30000>;

		L1I: pm_v8i_l1: regulator-pm-v8i-l1 {
			regulator-name = "pm_v8i_l1";
			qcom,set = <RPMH_REGULATOR_SET_ALL>;
			regulator-min-microvolt = <1200000>;
			regulator-max-microvolt = <1200000>;
			qcom,init-voltage = <1200000>;
			qcom,init-mode = <RPMH_REGULATOR_MODE_HPM>;
		};
	};

	rpmh-regulator-ldoi2 {
		compatible = "qcom,rpmh-vrm-regulator";
		qcom,resource-name = "ldoi2";
		qcom,regulator-type = "pmic5-ldo";
		qcom,supported-modes =
			<RPMH_REGULATOR_MODE_RET
			 RPMH_REGULATOR_MODE_HPM>;
		qcom,mode-threshold-currents = <0 30000>;

		L2I: pm_v8i_l2: regulator-pm-v8i-l2 {
			regulator-name = "pm_v8i_l2";
			qcom,set = <RPMH_REGULATOR_SET_ALL>;
			regulator-min-microvolt = <1200000>;
			regulator-max-microvolt = <1200000>;
			qcom,init-voltage = <1200000>;
			qcom,init-mode = <RPMH_REGULATOR_MODE_HPM>;
		};
	};

	rpmh-regulator-ldoi3 {
		compatible = "qcom,rpmh-vrm-regulator";
		qcom,resource-name = "ldoi3";
		qcom,regulator-type = "pmic5-ldo";
		qcom,supported-modes =
			<RPMH_REGULATOR_MODE_LPM
			 RPMH_REGULATOR_MODE_HPM>;
		qcom,mode-threshold-currents = <0 30000>;
		proxy-supply = <&L3I>;

		L3I: pm_v8i_l3: regulator-pm-v8i-l3 {
			regulator-name = "pm_v8i_l3";
			qcom,set = <RPMH_REGULATOR_SET_ALL>;
			regulator-min-microvolt = <880000>;
			regulator-max-microvolt = <912000>;
			qcom,init-voltage = <880000>;
			qcom,init-mode = <RPMH_REGULATOR_MODE_HPM>;
			qcom,proxy-consumer-enable;
		};
	};

	rpmh-regulator-smpj2 {
		compatible = "qcom,rpmh-vrm-regulator";
		qcom,resource-name = "smpj2";

		S2J: pm_v6j_s2: regulator-pm-v6j-s2 {
			regulator-name = "pm_v6j_s2";
			qcom,set = <RPMH_REGULATOR_SET_ALL>;
			regulator-min-microvolt = <1000000>;
			regulator-max-microvolt = <1100000>;
			qcom,init-voltage = <1080000>;
		};
	};

	rpmh-regulator-smpj3 {
		compatible = "qcom,rpmh-vrm-regulator";
		qcom,resource-name = "smpj3";

		S3J: pm_v6j_s3: regulator-pm-v6j-s3 {
			regulator-name = "pm_v6j_s3";
			qcom,set = <RPMH_REGULATOR_SET_ALL>;
			regulator-min-microvolt = <1000000>;
			regulator-max-microvolt = <1100000>;
			qcom,init-voltage = <1052000>;
		};
	};

	VRM_S4J: rpmh-regulator-smpj4 {
		compatible = "qcom,rpmh-vrm-regulator";
		qcom,resource-name = "smpj4";

		S4J: pm_v6j_s4: regulator-pm-v6j-s4 {
			regulator-name = "pm_v6j_s4";
			qcom,set = <RPMH_REGULATOR_SET_ALL>;
			regulator-min-microvolt = <500000>;
			regulator-max-microvolt = <1000000>;
			qcom,init-voltage = <852000>;
		};
	};

	rpmh-regulator-ldoj1 {
		compatible = "qcom,rpmh-vrm-regulator";
		qcom,resource-name = "ldoj1";
		qcom,regulator-type = "pmic5-ldo";
		qcom,supported-modes =
			<RPMH_REGULATOR_MODE_LPM
			 RPMH_REGULATOR_MODE_HPM>;
		qcom,mode-threshold-currents = <0 30000>;

		L1J: pm_v6j_l1: regulator-pm-v6j-l1 {
			regulator-name = "pm_v6j_l1";
			qcom,set = <RPMH_REGULATOR_SET_ALL>;
			regulator-min-microvolt = <880000>;
			regulator-max-microvolt = <920000>;
			qcom,init-voltage = <912000>;
			qcom,init-mode = <RPMH_REGULATOR_MODE_HPM>;
		};
	};

	rpmh-regulator-ldoj2 {
		compatible = "qcom,rpmh-vrm-regulator";
		qcom,resource-name = "ldoj2";
		qcom,regulator-type = "pmic5-ldo";
		qcom,supported-modes =
			<RPMH_REGULATOR_MODE_RET
			 RPMH_REGULATOR_MODE_HPM>;
		qcom,mode-threshold-currents = <0 30000>;

		L2J: pm_v6j_l2: regulator-pm-v6j-l2 {
			regulator-name = "pm_v6j_l2";
			qcom,set = <RPMH_REGULATOR_SET_ALL>;
			regulator-min-microvolt = <1200000>;
			regulator-max-microvolt = <1200000>;
			qcom,init-voltage = <1200000>;
			qcom,init-mode = <RPMH_REGULATOR_MODE_HPM>;
		};
	};

	rpmh-regulator-ldok1 {
		compatible = "qcom,rpmh-vrm-regulator";
		qcom,resource-name = "ldok1";
		qcom,regulator-type = "pmic5-ldo";
		qcom,supported-modes =
			<RPMH_REGULATOR_MODE_LPM
			 RPMH_REGULATOR_MODE_HPM>;
		qcom,mode-threshold-currents = <0 30000>;

		L1K: pmr_nalojr_l1: regulator-pmr-nalojr-l1 {
			regulator-name = "pmr_nalojr_l1";
			qcom,set = <RPMH_REGULATOR_SET_ALL>;
			regulator-min-microvolt = <400000>;
			regulator-max-microvolt = <920000>;
			qcom,init-voltage = <856000>;
			qcom,init-mode = <RPMH_REGULATOR_MODE_HPM>;
		};
	};

	rpmh-regulator-ldok2 {
		compatible = "qcom,rpmh-vrm-regulator";
		qcom,resource-name = "ldok2";
		qcom,regulator-type = "pmic5-ldo";
		qcom,supported-modes =
			<RPMH_REGULATOR_MODE_LPM
			 RPMH_REGULATOR_MODE_HPM>;
		qcom,mode-threshold-currents = <0 30000>;

		L2K: pmr_nalojr_l2: regulator-pmr-nalojr-l2 {
			regulator-name = "pmr_nalojr_l2";
			qcom,set = <RPMH_REGULATOR_SET_ALL>;
			regulator-min-microvolt = <912000>;
			regulator-max-microvolt = <1000000>;
			qcom,init-voltage = <912000>;
			qcom,init-mode = <RPMH_REGULATOR_MODE_HPM>;
		};
	};

	rpmh-regulator-ldok3 {
		compatible = "qcom,rpmh-vrm-regulator";
		qcom,resource-name = "ldok3";
		qcom,regulator-type = "pmic5-ldo";
		qcom,supported-modes =
			<RPMH_REGULATOR_MODE_LPM
			 RPMH_REGULATOR_MODE_HPM>;
		qcom,mode-threshold-currents = <0 30000>;

		L3K: pmr_nalojr_l3: regulator-pmr-nalojr-l3 {
			regulator-name = "pmr_nalojr_l3";
			qcom,set = <RPMH_REGULATOR_SET_ALL>;
			regulator-min-microvolt = <1200000>;
			regulator-max-microvolt = <1200000>;
			qcom,init-voltage = <1200000>;
			qcom,init-mode = <RPMH_REGULATOR_MODE_HPM>;
		};
	};

	rpmh-regulator-ldok4 {
		compatible = "qcom,rpmh-vrm-regulator";
		qcom,resource-name = "ldok4";
		qcom,regulator-type = "pmic5-ldo";
		qcom,supported-modes =
			<RPMH_REGULATOR_MODE_LPM
			 RPMH_REGULATOR_MODE_HPM>;
		qcom,mode-threshold-currents = <0 30000>;

		L4K: pmr_nalojr_l4: regulator-pmr-nalojr-l4 {
			regulator-name = "pmr_nalojr_l4";
			qcom,set = <RPMH_REGULATOR_SET_ALL>;
			regulator-min-microvolt = <1200000>;
			regulator-max-microvolt = <1200000>;
			qcom,init-voltage = <1200000>;
			qcom,init-mode = <RPMH_REGULATOR_MODE_HPM>;
		};
	};

	rpmh-regulator-ldok5 {
		compatible = "qcom,rpmh-vrm-regulator";
		qcom,resource-name = "ldok5";
		qcom,regulator-type = "pmic5-ldo";
		qcom,supported-modes =
			<RPMH_REGULATOR_MODE_LPM
			 RPMH_REGULATOR_MODE_HPM>;
		qcom,mode-threshold-currents = <0 30000>;

		L5K: pmr_nalojr_l5: regulator-pmr-nalojr-l5 {
			regulator-name = "pmr_nalojr_l5";
			qcom,set = <RPMH_REGULATOR_SET_ALL>;
			regulator-min-microvolt = <952000>;
			regulator-max-microvolt = <976000>;
			qcom,init-voltage = <952000>;
			qcom,init-mode = <RPMH_REGULATOR_MODE_HPM>;
		};
	};

	rpmh-regulator-ldok6 {
		compatible = "qcom,rpmh-vrm-regulator";
		qcom,resource-name = "ldok6";
		qcom,regulator-type = "pmic5-ldo";
		qcom,supported-modes =
			<RPMH_REGULATOR_MODE_LPM
			 RPMH_REGULATOR_MODE_HPM>;
		qcom,mode-threshold-currents = <0 30000>;

		L6K: pmr_nalojr_l6: regulator-pmr-nalojr-l6 {
			regulator-name = "pmr_nalojr_l6";
			qcom,set = <RPMH_REGULATOR_SET_ALL>;
			regulator-min-microvolt = <1776000>;
			regulator-max-microvolt = <1860000>;
			qcom,init-voltage = <1776000>;
			qcom,init-mode = <RPMH_REGULATOR_MODE_HPM>;
		};
	};

	rpmh-regulator-ldok7 {
		compatible = "qcom,rpmh-vrm-regulator";
		qcom,resource-name = "ldok7";
		qcom,regulator-type = "pmic5-ldo";
		qcom,supported-modes =
			<RPMH_REGULATOR_MODE_LPM
			 RPMH_REGULATOR_MODE_HPM>;
		qcom,mode-threshold-currents = <0 30000>;

		L7K: pmr_nalojr_l7: regulator-pmr-nalojr-l7 {
			regulator-name = "pmr_nalojr_l7";
			qcom,set = <RPMH_REGULATOR_SET_ALL>;
			regulator-min-microvolt = <800000>;
			regulator-max-microvolt = <800000>;
			qcom,init-voltage = <800000>;
			qcom,init-mode = <RPMH_REGULATOR_MODE_HPM>;
		};
	};

	rpmh-regulator-ldom1 {
		compatible = "qcom,rpmh-vrm-regulator";
		qcom,resource-name = "ldom1";
		qcom,regulator-type = "pmic5-ldo";
		qcom,supported-modes =
			<RPMH_REGULATOR_MODE_LPM
			 RPMH_REGULATOR_MODE_HPM>;
		qcom,mode-threshold-currents = <0 30000>;

		L1M: pm8010m_l1: regulator-pm8010m-l1 {
			regulator-name = "pm8010m_l1";
			qcom,set = <RPMH_REGULATOR_SET_ALL>;
			regulator-min-microvolt = <1104000>;
			regulator-max-microvolt = <1104000>;
			qcom,init-voltage = <1104000>;
			qcom,init-mode = <RPMH_REGULATOR_MODE_HPM>;
		};
	};

	rpmh-regulator-ldom2 {
		compatible = "qcom,rpmh-vrm-regulator";
		qcom,resource-name = "ldom2";
		qcom,regulator-type = "pmic5-ldo";
		qcom,supported-modes =
			<RPMH_REGULATOR_MODE_LPM
			 RPMH_REGULATOR_MODE_HPM>;
		qcom,mode-threshold-currents = <0 30000>;

		L2M: pm8010m_l2: regulator-pm8010m-l2 {
			regulator-name = "pm8010m_l2";
			qcom,set = <RPMH_REGULATOR_SET_ALL>;
			regulator-min-microvolt = <1056000>;
			regulator-max-microvolt = <1056000>;
			qcom,init-voltage = <1056000>;
			qcom,init-mode = <RPMH_REGULATOR_MODE_HPM>;
		};
	};

	rpmh-regulator-ldom3 {
		compatible = "qcom,rpmh-vrm-regulator";
		qcom,resource-name = "ldom3";

		L3M: pm8010m_l3: regulator-pm8010m-l3 {
			regulator-name = "pm8010m_l3";
			qcom,set = <RPMH_REGULATOR_SET_ALL>;
			regulator-min-microvolt = <2800000>;
			regulator-max-microvolt = <2800000>;
			qcom,init-voltage = <2800000>;
		};
	};

	rpmh-regulator-ldom4 {
		compatible = "qcom,rpmh-vrm-regulator";
		qcom,resource-name = "ldom4";

		L4M: pm8010m_l4: regulator-pm8010m-l4 {
			regulator-name = "pm8010m_l4";
			qcom,set = <RPMH_REGULATOR_SET_ALL>;
			regulator-min-microvolt = <2800000>;
			regulator-max-microvolt = <2800000>;
			qcom,init-voltage = <2800000>;
		};
	};

	rpmh-regulator-ldom5 {
		compatible = "qcom,rpmh-vrm-regulator";
		qcom,resource-name = "ldom5";

		L5M: pm8010m_l5: regulator-pm8010m-l5 {
			regulator-name = "pm8010m_l5";
			qcom,set = <RPMH_REGULATOR_SET_ALL>;
			regulator-min-microvolt = <1800000>;
			regulator-max-microvolt = <1800000>;
			qcom,init-voltage = <1800000>;
		};
	};

	rpmh-regulator-ldom6 {
		compatible = "qcom,rpmh-vrm-regulator";
		qcom,resource-name = "ldom6";

		L6M: pm8010m_l6: regulator-pm8010m-l6 {
			regulator-name = "pm8010m_l6";
			qcom,set = <RPMH_REGULATOR_SET_ALL>;
			regulator-min-microvolt = <2800000>;
			regulator-max-microvolt = <2800000>;
			qcom,init-voltage = <2800000>;
		};
	};

	rpmh-regulator-ldom7 {
		compatible = "qcom,rpmh-vrm-regulator";
		qcom,resource-name = "ldom7";

		L7M: pm8010m_l7: regulator-pm8010m-l7 {
			regulator-name = "pm8010m_l7";
			qcom,set = <RPMH_REGULATOR_SET_ALL>;
			regulator-min-microvolt = <2960000>;
			regulator-max-microvolt = <2960000>;
			qcom,init-voltage = <2960000>;
		};
	};

	rpmh-regulator-ldon1 {
		compatible = "qcom,rpmh-vrm-regulator";
		qcom,resource-name = "ldon1";
		qcom,regulator-type = "pmic5-ldo";
		qcom,supported-modes =
			<RPMH_REGULATOR_MODE_LPM
			 RPMH_REGULATOR_MODE_HPM>;
		qcom,mode-threshold-currents = <0 30000>;

		L1N: pm8010n_l1: regulator-pm8010n-l1 {
			regulator-name = "pm8010n_l1";
			qcom,set = <RPMH_REGULATOR_SET_ALL>;
			regulator-min-microvolt = <1104000>;
			regulator-max-microvolt = <1104000>;
			qcom,init-voltage = <1104000>;
			qcom,init-mode = <RPMH_REGULATOR_MODE_HPM>;
		};
	};

	rpmh-regulator-ldon2 {
		compatible = "qcom,rpmh-vrm-regulator";
		qcom,resource-name = "ldon2";
		qcom,regulator-type = "pmic5-ldo";
		qcom,supported-modes =
			<RPMH_REGULATOR_MODE_LPM
			 RPMH_REGULATOR_MODE_HPM>;
		qcom,mode-threshold-currents = <0 30000>;

		L2N: pm8010n_l2: regulator-pm8010n-l2 {
			regulator-name = "pm8010n_l2";
			qcom,set = <RPMH_REGULATOR_SET_ALL>;
			regulator-min-microvolt = <1104000>;
			regulator-max-microvolt = <1104000>;
			qcom,init-voltage = <1104000>;
			qcom,init-mode = <RPMH_REGULATOR_MODE_HPM>;
		};
	};

	rpmh-regulator-ldon3 {
		compatible = "qcom,rpmh-vrm-regulator";
		qcom,resource-name = "ldon3";

		L3N: pm8010n_l3: regulator-pm8010n-l3 {
			regulator-name = "pm8010n_l3";
			qcom,set = <RPMH_REGULATOR_SET_ALL>;
			regulator-min-microvolt = <1800000>;
			regulator-max-microvolt = <1800000>;
			qcom,init-voltage = <1800000>;
		};
	};

	rpmh-regulator-ldon4 {
		compatible = "qcom,rpmh-vrm-regulator";
		qcom,resource-name = "ldon4";

		L4N: pm8010n_l4: regulator-pm8010n-l4 {
			regulator-name = "pm8010n_l4";
			qcom,set = <RPMH_REGULATOR_SET_ALL>;
			regulator-min-microvolt = <1800000>;
			regulator-max-microvolt = <1800000>;
			qcom,init-voltage = <1800000>;
		};
	};

	rpmh-regulator-ldon5 {
		compatible = "qcom,rpmh-vrm-regulator";
		qcom,resource-name = "ldon5";

		L5N: pm8010n_l5: regulator-pm8010n-l5 {
			regulator-name = "pm8010n_l5";
			qcom,set = <RPMH_REGULATOR_SET_ALL>;
			regulator-min-microvolt = <2800000>;
			regulator-max-microvolt = <2800000>;
			qcom,init-voltage = <2800000>;
		};
	};

	rpmh-regulator-ldon6 {
		compatible = "qcom,rpmh-vrm-regulator";
		qcom,resource-name = "ldon6";

		L6N: pm8010n_l6: regulator-pm8010n-l6 {
			regulator-name = "pm8010n_l6";
			qcom,set = <RPMH_REGULATOR_SET_ALL>;
			regulator-min-microvolt = <2800000>;
			regulator-max-microvolt = <2800000>;
			qcom,init-voltage = <2800000>;
		};
	};

	rpmh-regulator-ldon7 {
		compatible = "qcom,rpmh-vrm-regulator";
		qcom,resource-name = "ldon7";

		L7N: pm8010n_l7: regulator-pm8010n-l7 {
			regulator-name = "pm8010n_l7";
			qcom,set = <RPMH_REGULATOR_SET_ALL>;
			regulator-min-microvolt = <3304000>;
			regulator-max-microvolt = <3304000>;
			qcom,init-voltage = <3304000>;
		};
	};
};
